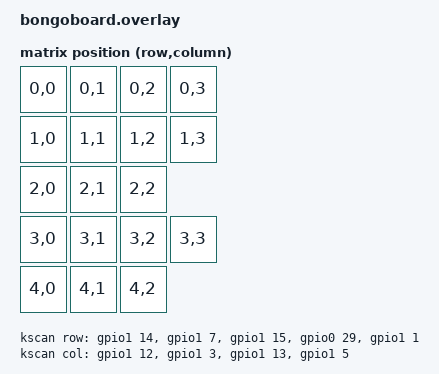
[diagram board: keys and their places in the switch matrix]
// This file was generated from a template. Edit it to match your keyboard.
// See https://zmk.dev for more instructions.

#include <dt-bindings/zmk/matrix_transform.h>
#include "bongoboard-layouts.dtsi"

// Hardware Pin Reminders from Chart:
// i2c_scl, D4, P0.04
// i2c_sda, D15, P0.10
// enc_B, D16, P0.31
// enc_A, D6, P1.11

/ {
    chosen {
        zmk,physical-layout = &default_layout;
    };

    kscan: kscan {
        compatible = "zmk,kscan-gpio-matrix";
        diode-direction = "col2row";
        wakeup-source;

        col-gpios
            = <&gpio1 12 GPIO_ACTIVE_HIGH> // col0 = D7 (P1.12)
            , <&gpio1 3  GPIO_ACTIVE_HIGH> // col1 = D17 (P1.03)
            , <&gpio1 13 GPIO_ACTIVE_HIGH> // col2 = D8 (P1.13)
            , <&gpio1 5  GPIO_ACTIVE_HIGH> // col3 = D18 (P1.05)
            ;

        row-gpios
            = <&gpio1 14 (GPIO_ACTIVE_HIGH | GPIO_PULL_DOWN)> // row0 = D9 (P1.14)
            , <&gpio1 7  (GPIO_ACTIVE_HIGH | GPIO_PULL_DOWN)> // row1 = D19 (P1.07)
            , <&gpio1 15 (GPIO_ACTIVE_HIGH | GPIO_PULL_DOWN)> // row2 = D10 (P1.15)
            , <&gpio0 29 (GPIO_ACTIVE_HIGH | GPIO_PULL_DOWN)> // row3 = D3 (P0.29)
            , <&gpio1 1  (GPIO_ACTIVE_HIGH | GPIO_PULL_DOWN)> // row4 = D13 (P1.01)
            ;
    };

    default_transform: default_transform {
        compatible = "zmk,matrix-transform";
        columns = <4>;
        rows = <5>;

        map = <
            RC(0, 0) RC(0, 1) RC(0, 2) RC(0, 3)
            RC(1, 0) RC(1, 1) RC(1, 2) RC(1, 3)
            RC(2, 0) RC(2, 1) RC(2, 2) /* Blank */
            RC(3, 0) RC(3, 1) RC(3, 2) RC(3, 3)
            RC(4, 0) RC(4, 1) RC(4, 2) /* Blank */
        >;
    };
};
